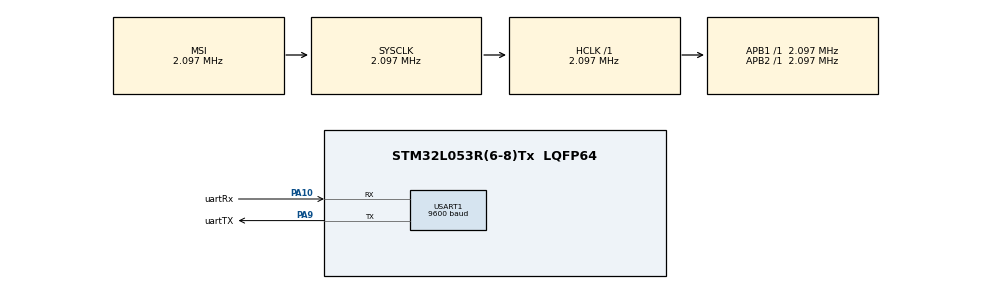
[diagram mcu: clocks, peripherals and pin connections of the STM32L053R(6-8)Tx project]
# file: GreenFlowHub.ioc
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Mcu.Family=STM32L0
Mcu.Name=STM32L053R(6-8)Tx
Mcu.Package=LQFP64
NVIC.USART1_IRQn=true\:0\:0\:false\:false\:true
PA10.GPIO_Label=uartRx
PA10.GPIO_Speed=GPIO_SPEED_FREQ_HIGH
PA10.Mode=Asynchronous
PA10.Signal=USART1_RX
PA9.GPIO_Label=uartTX
PA9.GPIO_Speed=GPIO_SPEED_FREQ_HIGH
PA9.Mode=Asynchronous
PA9.Signal=USART1_TX
ProjectManager.HeapSize=0x200
ProjectManager.StackSize=0x400
ProjectManager.TargetToolchain=EWARM
RCC.AHBFreq_Value=2097000
RCC.APB1Freq_Value=2097000
RCC.APB1TimFreq_Value=2097000
RCC.APB2Freq_Value=2097000
RCC.APB2TimFreq_Value=2097000
RCC.HCLKFreq_Value=2097000
RCC.HSE_VALUE=8000000
RCC.HSI16_VALUE=16000000
RCC.HSI48_VALUE=48000000
RCC.HSI_VALUE=16000000
RCC.LSE_VALUE=32768
RCC.MSI_VALUE=2097000
RCC.SYSCLKFreq_VALUE=2097000
RCC.VCOOutputFreq_Value=48000000
USART1.BaudRate=9600
USART1.VirtualMode-Asynchronous=VM_ASYNC
USART1.WordLength=WORDLENGTH_8B
board=GreenFlowHub

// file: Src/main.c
/**
  ******************************************************************************
  * File Name          : main.c
  * Description        : Main program body
  ******************************************************************************
  *
  * COPYRIGHT(c) 2017 STMicroelectronics
  *
  * Redistribution and use in source and binary forms, with or without modification,
  * are permitted provided that the following conditions are met:
  *   1. Redistributions of source code must retain the above copyright notice,
  *      this list of conditions and the following disclaimer.
  *   2. Redistributions in binary form must reproduce the above copyright notice,
  *      this list of conditions and the following disclaimer in the documentation
  *      and/or other materials provided with the distribution.
  *   3. Neither the name of STMicroelectronics nor the names of its contributors
  *      may be used to endorse or promote products derived from this software
  *      without specific prior written permission.
  *
  * THIS SOFTWARE IS PROVIDED BY THE COPYRIGHT HOLDERS AND CONTRIBUTORS "AS IS"
  * AND ANY EXPRESS OR IMPLIED WARRANTIES, INCLUDING, BUT NOT LIMITED TO, THE
  * IMPLIED WARRANTIES OF MERCHANTABILITY AND FITNESS FOR A PARTICULAR PURPOSE ARE
  * DISCLAIMED. IN NO EVENT SHALL THE COPYRIGHT HOLDER OR CONTRIBUTORS BE LIABLE
  * FOR ANY DIRECT, INDIRECT, INCIDENTAL, SPECIAL, EXEMPLARY, OR CONSEQUENTIAL
  * DAMAGES (INCLUDING, BUT NOT LIMITED TO, PROCUREMENT OF SUBSTITUTE GOODS OR
  * SERVICES; LOSS OF USE, DATA, OR PROFITS; OR BUSINESS INTERRUPTION) HOWEVER
  * CAUSED AND ON ANY THEORY OF LIABILITY, WHETHER IN CONTRACT, STRICT LIABILITY,
  * OR TORT (INCLUDING NEGLIGENCE OR OTHERWISE) ARISING IN ANY WAY OUT OF THE USE
  * OF THIS SOFTWARE, EVEN IF ADVISED OF THE POSSIBILITY OF SUCH DAMAGE.
  *
  ******************************************************************************
  */
#include "main.h"
#include "stm32l0xx_hal.h"

/* USER CODE BEGIN Includes */
#include "mainThread.h"
/* USER CODE END Includes */

UART_HandleTypeDef huart1;

/* USER CODE BEGIN PV */
/* Private variables ---------------------------------------------------------*/

/* USER CODE END PV */

void SystemClock_Config(void);
void Error_Handler(void);
static void MX_GPIO_Init(void);
static void MX_USART1_UART_Init(void);

/* USER CODE BEGIN PFP */
/* Private function prototypes -----------------------------------------------*/

/* USER CODE END PFP */

int main(void)
{

  /* MCU Configuration----------------------------------------------------------*/

  /* Reset of all peripherals, Initializes the Flash interface and the Systick. */
  HAL_Init();

  /* Configure the system clock */
  SystemClock_Config();

  /* Initialize all configured peripherals */
  MX_GPIO_Init();
  MX_USART1_UART_Init();

  /* USER CODE BEGIN 2 */
  int errorCode = 0;
  errorCode = initMainThread(&huart1);
  char newValue = 0;
  /* USER CODE END 2 */

  /* Infinite loop */
  /* USER CODE BEGIN WHILE */
  while (1)
  {
    uint8_t outputChar[3] = {0x55, 0xCC, 0x00};
    uint8_t inputChar[3] = {0,0,0};
    // HAL_UART_Transmit(UART_HandleTypeDef *huart, uint8_t *pData, uint16_t Size, uint32_t Timeout)
    //char errorCode =HAL_UART_Transmit(uio_uartHandler, outputChar, 3, 1000);
    HAL_Delay(500);
    //HAL_UART_Receive(UART_HandleTypeDef *huart, uint8_t *pData, uint16_t Size, uint32_t Timeout);
    newValue++;
    outputChar[2] = newValue;
    errorCode = HAL_UART_Transmit(&huart1, outputChar, 3, 1000);

    errorCode = mainThread();
    //fatal error has occured restart board
    if(errorCode)
    {
      //TODO: deal with fatal error with system reset
      while(1);
    }
  /* USER CODE END WHILE */

  }

}

/** System Clock Configuration
*/
void SystemClock_Config(void)
{

  RCC_OscInitTypeDef RCC_OscInitStruct;
  RCC_ClkInitTypeDef RCC_ClkInitStruct;
  RCC_PeriphCLKInitTypeDef PeriphClkInit;

    /**Configure the main internal regulator output voltage
    */
  __HAL_PWR_VOLTAGESCALING_CONFIG(PWR_REGULATOR_VOLTAGE_SCALE1);

    /**Initializes the CPU, AHB and APB busses clocks
    */
  RCC_OscInitStruct.OscillatorType = RCC_OSCILLATORTYPE_MSI;
  RCC_OscInitStruct.MSIState = RCC_MSI_ON;
  RCC_OscInitStruct.MSICalibrationValue = 0;
  RCC_OscInitStruct.MSIClockRange = RCC_MSIRANGE_5;
  RCC_OscInitStruct.PLL.PLLState = RCC_PLL_NONE;
  if (HAL_RCC_OscConfig(&RCC_OscInitStruct) != HAL_OK)
  {
    Error_Handler();
  }

    /**Initializes the CPU, AHB and APB busses clocks
    */
  RCC_ClkInitStruct.ClockType = RCC_CLOCKTYPE_HCLK|RCC_CLOCKTYPE_SYSCLK
                              |RCC_CLOCKTYPE_PCLK1|RCC_CLOCKTYPE_PCLK2;
  RCC_ClkInitStruct.SYSCLKSource = RCC_SYSCLKSOURCE_MSI;
  RCC_ClkInitStruct.AHBCLKDivider = RCC_SYSCLK_DIV1;
  RCC_ClkInitStruct.APB1CLKDivider = RCC_HCLK_DIV1;
  RCC_ClkInitStruct.APB2CLKDivider = RCC_HCLK_DIV1;

  if (HAL_RCC_ClockConfig(&RCC_ClkInitStruct, FLASH_LATENCY_0) != HAL_OK)
  {
    Error_Handler();
  }

  PeriphClkInit.PeriphClockSelection = RCC_PERIPHCLK_USART1;
  PeriphClkInit.Usart1ClockSelection = RCC_USART1CLKSOURCE_PCLK2;
  if (HAL_RCCEx_PeriphCLKConfig(&PeriphClkInit) != HAL_OK)
  {
    Error_Handler();
  }

    /**Configure the Systick interrupt time
    */
  HAL_SYSTICK_Config(HAL_RCC_GetHCLKFreq()/1000);

    /**Configure the Systick
    */
  HAL_SYSTICK_CLKSourceConfig(SYSTICK_CLKSOURCE_HCLK);

  /* SysTick_IRQn interrupt configuration */
  HAL_NVIC_SetPriority(SysTick_IRQn, 0, 0);
}

/* USART1 init function */
static void MX_USART1_UART_Init(void)
{

  huart1.Instance = USART1;
  huart1.Init.BaudRate = 9600;
  huart1.Init.WordLength = UART_WORDLENGTH_8B;
  huart1.Init.StopBits = UART_STOPBITS_1;
  huart1.Init.Parity = UART_PARITY_NONE;
  huart1.Init.Mode = UART_MODE_TX_RX;
  huart1.Init.HwFlowCtl = UART_HWCONTROL_NONE;
  huart1.Init.OverSampling = UART_OVERSAMPLING_16;
  huart1.Init.OneBitSampling = UART_ONE_BIT_SAMPLE_DISABLE;
  huart1.AdvancedInit.AdvFeatureInit = UART_ADVFEATURE_NO_INIT;
  if (HAL_UART_Init(&huart1) != HAL_OK)
  {
    Error_Handler();
  }

}

/** Pinout Configuration
*/
static void MX_GPIO_Init(void)
{

  /* GPIO Ports Clock Enable */
  __HAL_RCC_GPIOA_CLK_ENABLE();

}

void Error_Handler(void)
{
  while(1)
  {
  }
}

/************************ (C) COPYRIGHT STMicroelectronics *****END OF FILE****/
